# STM32F398VET6 register map
File version: 1.0
Registers are 32-bit, access not given, reset 0x0 unless marked. A register's access mark holds for its fields unless they carry their own. Offsets are from the block's base; [hi:lo] are bit positions; {n}, {i} and the like mark numbered series.

## PWR
Base 0x40007000
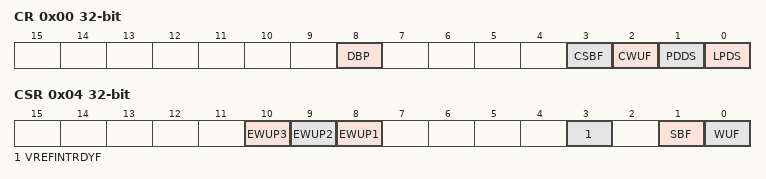
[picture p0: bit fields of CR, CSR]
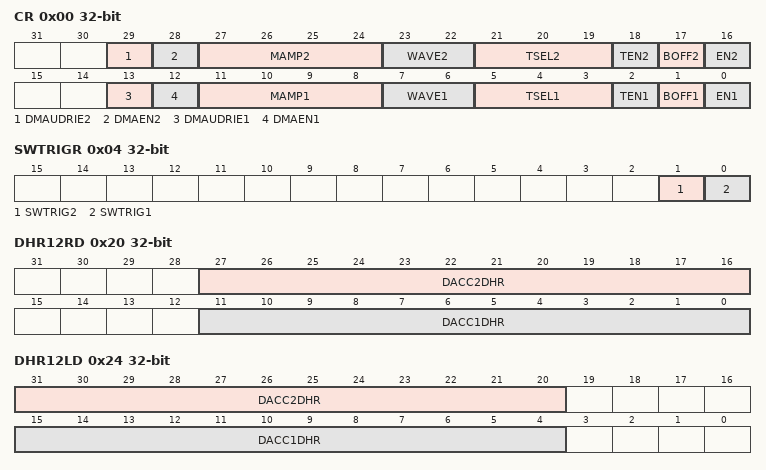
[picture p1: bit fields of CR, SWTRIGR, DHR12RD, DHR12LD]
0x00 CR
  [8] DBP, [3] CSBF, [2] CWUF, [1] PDDS, [0] LPDS
0x04 CSR
  [10] EWUP3, [9] EWUP2, [8] EWUP1, [3] VREFINTRDYF, [1] SBF, [0] WUF

## DAC
Base 0x40007400
0x00 CR
  [29] DMAUDRIE2, [28] DMAEN2, [27:24] MAMP2, [23:22] WAVE2, [21:19] TSEL2, [18] TEN2, [17] BOFF2, [16] EN2, [13] DMAUDRIE1, [12] DMAEN1, [11:8] MAMP1, [7:6] WAVE1, [5:3] TSEL1, [2] TEN1, [1] BOFF1, [0] EN1
0x04 SWTRIGR
  [1] SWTRIG2, [0] SWTRIG1
0x08 DHR12R1
  [11:0] DACC1DHR
0x0C DHR12L1
  [15:4] DACC1DHR
0x10 DHR8R1
  [7:0] DACC1DHR
0x14 DHR12R2
  [11:0] DACC2DHR
0x18 DHR12L2
  [15:4] DACC2DHR
0x1C DHR8R2
  [7:0] DACC2DHR
0x20 DHR12RD
  [27:16] DACC2DHR, [11:0] DACC1DHR
0x24 DHR12LD
  [31:20] DACC2DHR, [15:4] DACC1DHR
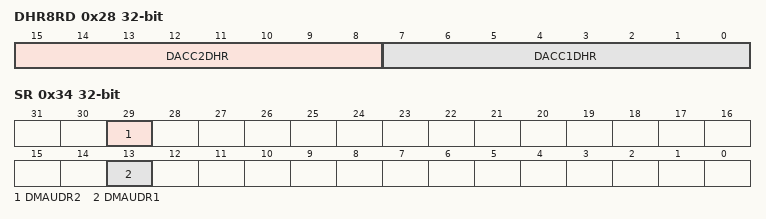
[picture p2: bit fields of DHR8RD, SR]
0x28 DHR8RD
  [15:8] DACC2DHR, [7:0] DACC1DHR
0x2C DOR1
  [11:0] DACC1DOR
0x30 DOR2
  [11:0] DACC2DOR
0x34 SR
  [29] DMAUDR2, [13] DMAUDR1

## DAC1
Base 0x40007400
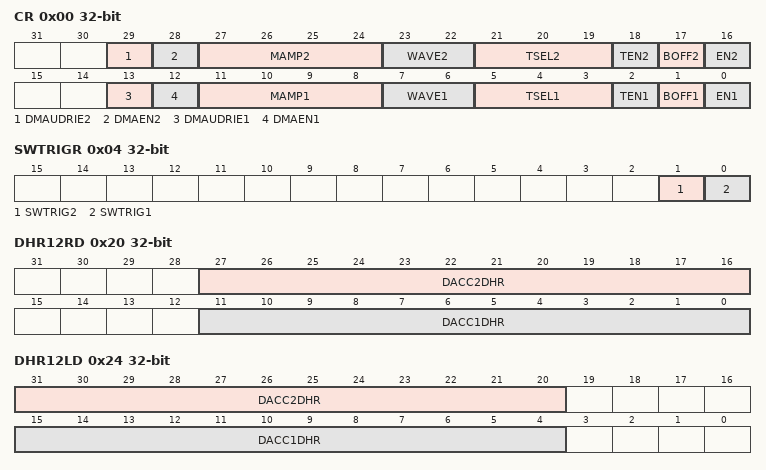
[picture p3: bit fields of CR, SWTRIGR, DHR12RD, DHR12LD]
0x00 CR
  [29] DMAUDRIE2, [28] DMAEN2, [27:24] MAMP2, [23:22] WAVE2, [21:19] TSEL2, [18] TEN2, [17] BOFF2, [16] EN2, [13] DMAUDRIE1, [12] DMAEN1, [11:8] MAMP1, [7:6] WAVE1, [5:3] TSEL1, [2] TEN1, [1] BOFF1, [0] EN1
0x04 SWTRIGR
  [1] SWTRIG2, [0] SWTRIG1
0x08 DHR12R1
  [11:0] DACC1DHR
0x0C DHR12L1
  [15:4] DACC1DHR
0x10 DHR8R1
  [7:0] DACC1DHR
0x14 DHR12R2
  [11:0] DACC2DHR
0x18 DHR12L2
  [15:4] DACC2DHR
0x1C DHR8R2
  [7:0] DACC2DHR
0x20 DHR12RD
  [27:16] DACC2DHR, [11:0] DACC1DHR
0x24 DHR12LD
  [31:20] DACC2DHR, [15:4] DACC1DHR
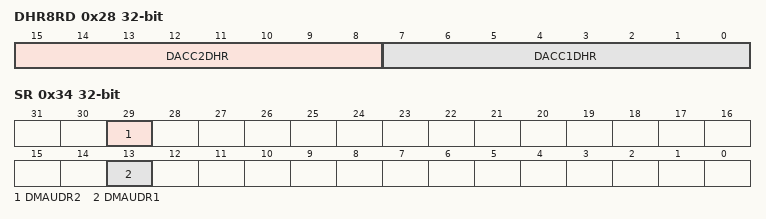
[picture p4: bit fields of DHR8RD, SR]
0x28 DHR8RD
  [15:8] DACC2DHR, [7:0] DACC1DHR
0x2C DOR1
  [11:0] DACC1DOR
0x30 DOR2
  [11:0] DACC2DOR
0x34 SR
  [29] DMAUDR2, [13] DMAUDR1

## SYSCFG
Base 0x40010000
0x00 CFGR1
  [31:26] FPU_IE, [24] I2C3_FMP, [23] ENCODER_MODE_TIM3, [22] ENCODER_MODE_TIM2, [21] I2C2_FMP, [20] I2C1_FMP, [n+10] I2C_PB{n}_FMP (n=6..9), [14] TIM7DAC1Ch2_DMA_RMP, [13] TIM6DAC1Ch1_DMA_RMP, [12] TIM17_DMA_RMP, [11] TIM16_DMA_RMP, [14:8] DMA_RMP, [7] DAC1_TRIG1_RMP, [6] TIM1_ITR3_RMP, [2:0] MEM_MODE
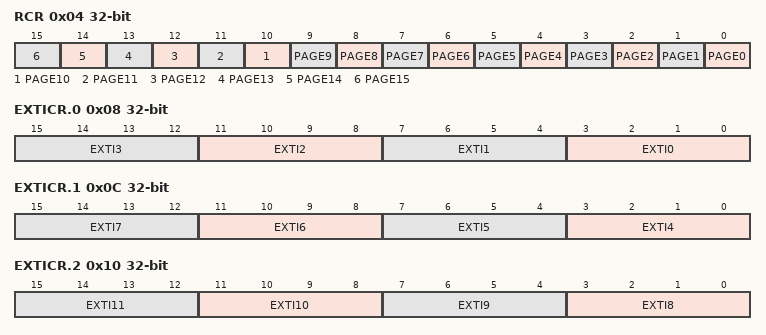
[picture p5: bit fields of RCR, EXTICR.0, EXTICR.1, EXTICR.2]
0x04 RCR
  [n] PAGE{n} (n=0..15)
0x08 EXTICR.0
  [4n+3:4n] EXTI{n} (n=0..3)
0x0C EXTICR.1
  [4n-13:4n-16] EXTI{n} (n=4..7)
0x10 EXTICR.2
  [4n-29:4n-32] EXTI{n} (n=8..11)
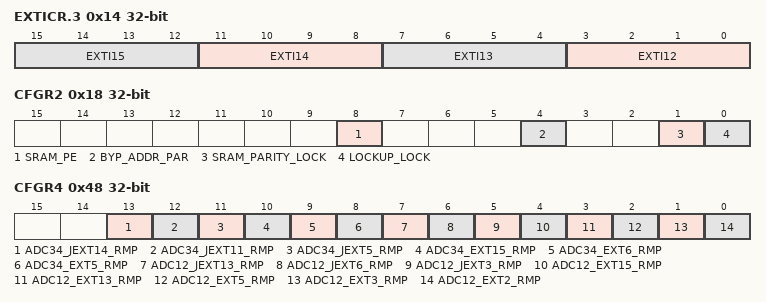
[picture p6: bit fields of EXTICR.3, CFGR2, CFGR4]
0x14 EXTICR.3
  [4n-45:4n-48] EXTI{n} (n=12..15)
0x18 CFGR2
  [8] SRAM_PE, [4] BYP_ADDR_PAR, [1] SRAM_PARITY_LOCK, [0] LOCKUP_LOCK
0x48 CFGR4
  [13] ADC34_JEXT14_RMP, [12] ADC34_JEXT11_RMP, [11] ADC34_JEXT5_RMP, [10] ADC34_EXT15_RMP, [9] ADC34_EXT6_RMP, [8] ADC34_EXT5_RMP, [7] ADC12_JEXT13_RMP, [6] ADC12_JEXT6_RMP, [5] ADC12_JEXT3_RMP, [4] ADC12_EXT15_RMP, [3] ADC12_EXT13_RMP, [2] ADC12_EXT5_RMP, [1] ADC12_EXT3_RMP, [0] ADC12_EXT2_RMP

## COMP1
Base 0x4001001C
Same registers: COMP2 0x40010020, COMP12_COMMON 0x40010020, COMP3 0x40010024, COMP4 0x40010028, COMP34_COMMON 0x40010028, COMP5 0x4001002C, COMP6 0x40010030, COMP56_COMMON 0x40010030, COMP7 0x40010034
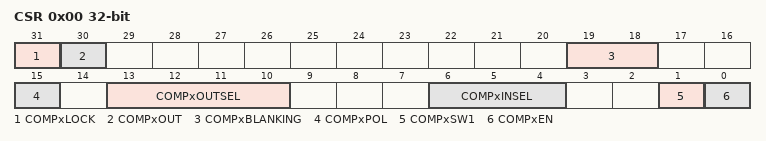
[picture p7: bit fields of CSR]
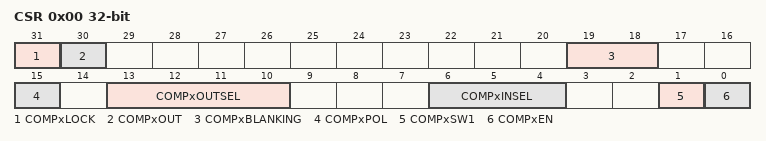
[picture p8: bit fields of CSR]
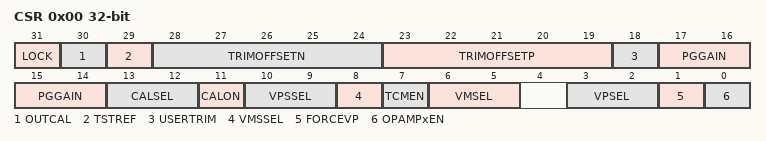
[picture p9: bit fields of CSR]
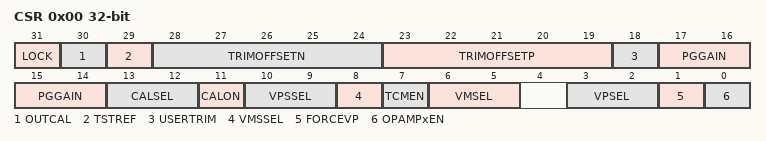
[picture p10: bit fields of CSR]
0x00 CSR
  [31] COMPxLOCK, [30] COMPxOUT, [19:18] COMPxBLANKING, [15] COMPxPOL, [13:10] COMPxOUTSEL, [6:4] COMPxINSEL, [1] COMPxSW1, [0] COMPxEN

## COMP
Base 0x4001001C
0x00 CSR
  [31] COMPxLOCK, [30] COMPxOUT, [19:18] COMPxBLANKING, [15] COMPxPOL, [13:10] COMPxOUTSEL, [6:4] COMPxINSEL, [1] COMPxSW1, [0] COMPxEN

## OPAMP1
Base 0x40010038
Same registers: OPAMP2 0x4001003C, OPAMP3 0x40010040, OPAMP4 0x40010044
0x00 CSR
  [31] LOCK, [30] OUTCAL, [29] TSTREF, [28:24] TRIMOFFSETN, [23:19] TRIMOFFSETP, [18] USERTRIM, [17:14] PGGAIN, [13:12] CALSEL, [11] CALON, [10:9] VPSSEL, [8] VMSSEL, [7] TCMEN, [6:5] VMSEL, [3:2] VPSEL, [1] FORCEVP, [0] OPAMPxEN

## OPAMP
Base 0x40010038
0x00 CSR
  [31] LOCK, [30] OUTCAL, [29] TSTREF, [28:24] TRIMOFFSETN, [23:19] TRIMOFFSETP, [18] USERTRIM, [17:14] PGGAIN, [13:12] CALSEL, [11] CALON, [10:9] VPSSEL, [8] VMSSEL, [7] TCMEN, [6:5] VMSEL, [3:2] VPSEL, [1] FORCEVP, [0] OPAMPxEN
